# TC37X register map
File version: 1.0.0
CPU: CM4 r0p1, little endian, MPU, FPU, VTOR, 3 interrupt priority bits
Registers are 16-bit, read-write, reset 0x0 unless marked. A register's access mark holds for its fields unless they carry their own. Offsets are from the block's base; [hi:lo] are bit positions; {n}, {i} and the like mark numbered series; 'fields as' and 'values as' point back to an identical list.

## SCU — ystem Control Unit
Base 0xF0036000
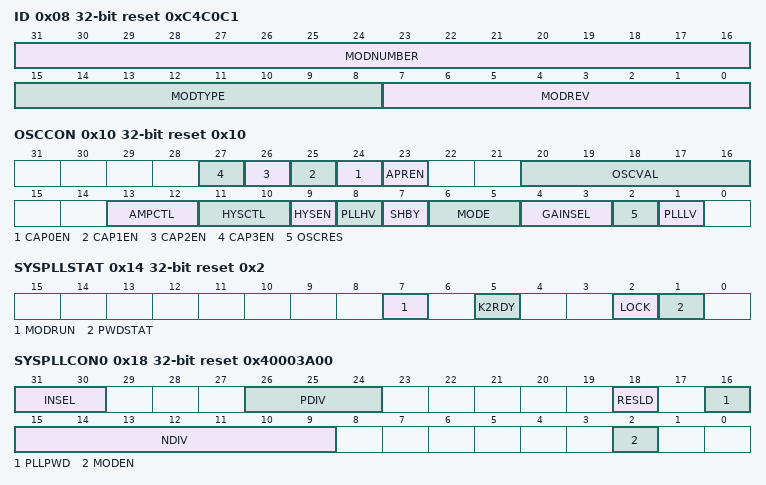
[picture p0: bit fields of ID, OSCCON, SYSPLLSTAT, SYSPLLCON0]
0x08 ID 32-bit ro reset 0xC4C0C1 — Identification Register
  [31:16] MODNUMBER — Module Number - MODNUMBER
  [15:8] MODTYPE — Module Type - MODTYPE
  [7:0] MODREV — Module Revision Number - MODREV
0x10 OSCCON 32-bit reset 0x10 (reset mask 0xFFFFF0F0) — OSC Control Register
  [n+24] CAP{n}EN (n=0..3) — Capacitance {n} Enable - CAP{n}EN
  [23] APREN — Amplitude Regulation Enable - APREN
  [20:16] OSCVAL — OSC Frequency Value - OSCVAL
  [13:12] AMPCTL — Amplitude Control
  [11:10] HYSCTL — Hysteresis Control
  [9] HYSEN — Hysteresis Enable
  [8] PLLHV ro — Oscillator for PLL Valid High Status Bit - PLLHV
  [7] SHBY — Shaper Bypass - SHBY
  [6:5] MODE — Oscillator Mode - MODE
  [4:3] GAINSEL — Oscillator Gain Selection - GAINSEL
  [2] OSCRES wo — Oscillator Watchdog Reset - OSCRES
  [1] PLLLV ro — Oscillator for PLL Valid Low Status Bit - PLLLV
0x14 SYSPLLSTAT 32-bit ro reset 0x2 — System PLL Status Register
  [7] MODRUN — Modulation Run - MODRUN
  [5] K2RDY — K2 Divider Ready Status - K2RDY
  [2] LOCK — System PLL Lock Status - LOCK
  [1] PWDSTAT — System PLL Power-saving Mode Status - PWDSTAT
0x18 SYSPLLCON0 32-bit reset 0x40003A00 — System PLL Configuration 0 Register
  [31:30] INSEL — Input Selection - INSEL
  [26:24] PDIV — P-Divider Value - PDIV
  [18] RESLD wo — Restart DCO Lock Detection - RESLD
  [16] PLLPWD — System PLL Power Saving Mode - PLLPWD
  [15:9] NDIV — N-Divider Value - NDIV
  [2] MODEN — Modulation Enable - MODEN
0x1C SYSPLLCON1 32-bit reset 0x5 — System PLL Configuration 1 Register
  [2:0] K2DIV — K2-Divider Value - K2DIV
0x20 SYSPLLCON2 32-bit reset 0x6000 — System PLL Configuration 2 Register
  [15:0] MODCFG — Modulation Configuration - MODCFG
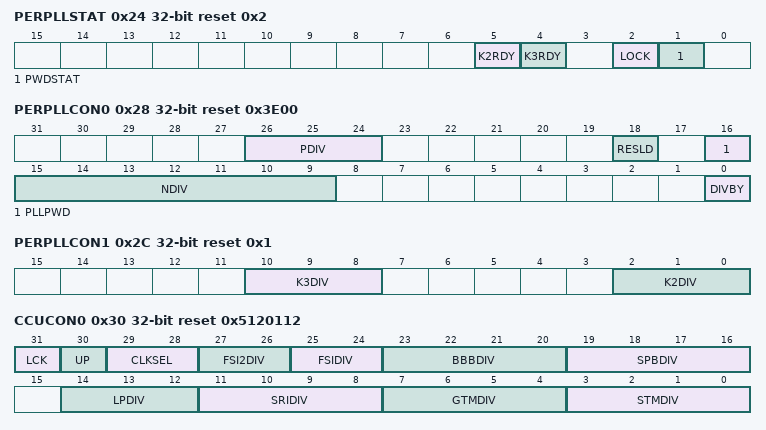
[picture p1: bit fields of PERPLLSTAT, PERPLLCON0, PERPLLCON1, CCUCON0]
0x24 PERPLLSTAT 32-bit ro reset 0x2 — Peripheral PLL Status Register
  [5] K2RDY — K2 Divider Ready Status - K2RDY
  [4] K3RDY — K3 Divider Ready Status - K3RDY
  [2] LOCK — Peripheral PLL Lock Status - LOCK
  [1] PWDSTAT — Peripheral PLL Power-saving Mode Status - PWDSTAT
0x28 PERPLLCON0 32-bit reset 0x3E00 — Peripheral PLL Configuration 0 Register
  [26:24] PDIV — P-Divider Value - PDIV
  [18] RESLD wo — Restart DCO Lock Detection - RESLD
  [16] PLLPWD — Peripheral PLL Power Saving Mode - PLLPWD
  [15:9] NDIV — N-Divider Value - NDIV
  [0] DIVBY — Divider Bypass - DIVBY
0x2C PERPLLCON1 32-bit reset 0x1 — Peripheral PLL Configuration 1 Register
  [10:8] K3DIV — K3-Divider Value - K3DIV
  [2:0] K2DIV — K2-Divider Value - K2DIV
0x30 CCUCON0 32-bit reset 0x5120112 — CCU Clock Control Register 0
  [31] LCK ro — Lock Status - LCK
  [30] UP wo — Update Request - UP
  [29:28] CLKSEL — Clock Selection for Source - CLKSEL
  [27:26] FSI2DIV — FSI2 Divider Reload Value - FSI2DIV
  [25:24] FSIDIV — FSI Divider Reload Value - FSIDIV
  [23:20] BBBDIV — BBB Divider Reload Value - BBBDIV
  [19:16] SPBDIV — SPB Divider Reload Value - SPBDIV
  [14:12] LPDIV — Low Power Divider Reload Value - LPDIV
  [11:8] SRIDIV — SRI Divider Reload Value - SRIDIV
  [7:4] GTMDIV — GTM Divider Reload Value - GTMDIV
  [3:0] STMDIV — STM Divider Reload Value - STMDIV
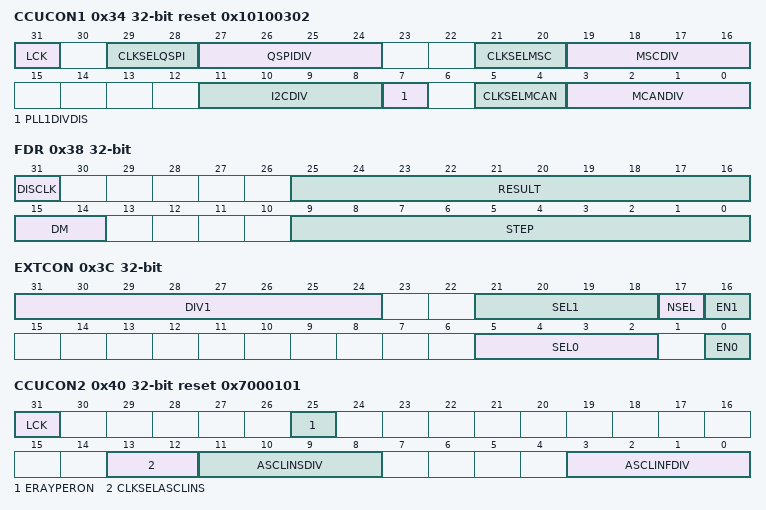
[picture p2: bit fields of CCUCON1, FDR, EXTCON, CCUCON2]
0x34 CCUCON1 32-bit reset 0x10100302 — CCU Clock Control Register 1
  [31] LCK ro — Lock Status - LCK
  [29:28] CLKSELQSPI — Clock Selection for QSPI - CLKSELQSPI
  [27:24] QSPIDIV — QSPI Divider Reload Value - QSPIDIV
  [21:20] CLKSELMSC — Clock Selection for MSC - CLKSELMSC
  [19:16] MSCDIV — MSC Divider Reload Value - MSCDIV
  [11:8] I2CDIV — I2C Divider Reload Value - I2CDIV
  [7] PLL1DIVDIS — Divider Disable for fPLL1 - PLL1DIVDIS
  [5:4] CLKSELMCAN — Clock Selection for MCAN - CLKSELMCAN
  [3:0] MCANDIV — MCAN Divider Reload Value - MCANDIV
0x38 FDR 32-bit — Fractional Divider Register
  [31] DISCLK — Disable Clock - DISCLK
  [25:16] RESULT ro — Result Value - RESULT
  [15:14] DM — Divider Mode - DM
  [9:0] STEP — Step Value - STEP
0x3C EXTCON 32-bit — External Clock Control Register
  [31:24] DIV1 — External Clock Divider for EXTCLK1 - DIV1
  [21:18] SEL1 — External Clock Select for EXTCLK1 - SEL1
  [17] NSEL — Negation Selection - NSEL
  [16] EN1 — External Clock Enable for EXTCLK1 - EN1
  [5:2] SEL0 — External Clock Select for EXTCLK0 - SEL0
  [0] EN0 — External Clock Enable for EXTCLK0 - EN0
0x40 CCUCON2 32-bit reset 0x7000101 — CCU Clock Control Register 2
  [31] LCK ro — Lock Status - LCK
  [25] ERAYPERON — Power Safe SwitchOff for ERAY Clock - ERAYPERON
  [13:12] CLKSELASCLINS — Clock Selection for ASCLINS - CLKSELASCLINS
  [11:8] ASCLINSDIV — ASCLIN Slow Divider Reload Value - ASCLINSDIV
  [3:0] ASCLINFDIV — ASCLIN Fast Divider Reload Value - ASCLINFDIV
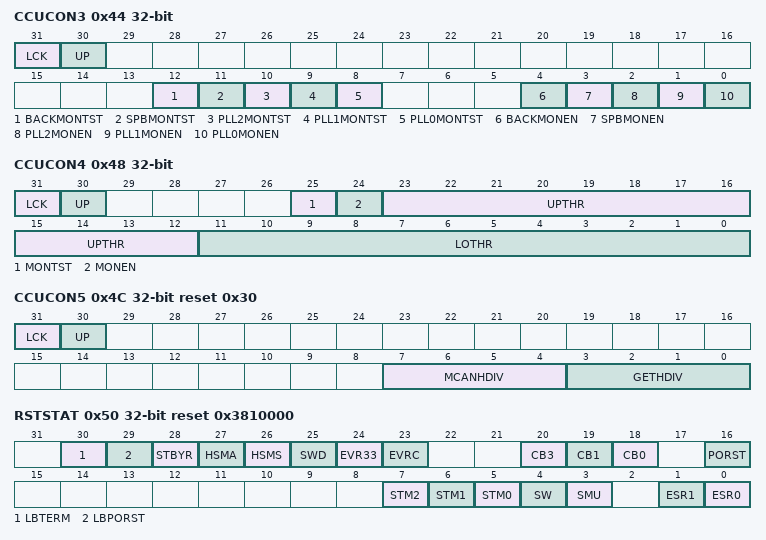
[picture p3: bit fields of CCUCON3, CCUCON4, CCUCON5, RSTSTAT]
0x44 CCUCON3 32-bit — CCU Clock Control Register 3
  [31] LCK ro — Lock Status - LCK
  [30] UP wo — Update Request - UP
  [12] BACKMONTST — Backup Clock Monitor Test - BACKMONTST
  [11] SPBMONTST — SPB Clock Monitor Test - SPBMONTST
  [10] PLL2MONTST — PLL2 Clock Monitor Test - PLL2MONTST
  [9] PLL1MONTST — PLL1 Clock Monitor Test - PLL1MONTST
  [8] PLL0MONTST — PLL0 Clock Monitor Test - PLL0MONTST
  [4] BACKMONEN — Backup Clock Monitor Enable - BACKMONEN
  [3] SPBMONEN — SPB Clock Monitor Enable - SPBMONEN
  [2] PLL2MONEN — PLL2 Clock Monitor Enable - PLL2MONEN
  [1] PLL1MONEN — PLL1 Clock Monitor Enable - PLL1MONEN
  [0] PLL0MONEN — PLL0 Clock Monitor Enable - PLL0MONEN
0x48 CCUCON4 32-bit — CCU Clock Control Register 4
  [31] LCK ro — Lock Status - LCK
  [30] UP wo — Update Request - UP
  [25] MONTST — Backup Clock Monitor Test - MONTST
  [24] MONEN — Backup Clock Monitor Enable - MONEN
  [23:12] UPTHR — Backup Clock Monitor Upper Threshold - UPTHR
  [11:0] LOTHR — Backup Clock Monitor Lower Threshold - LOTHR
0x4C CCUCON5 32-bit reset 0x30 — CCU Clock Control Register 5
  [31] LCK ro — Lock Status - LCK
  [30] UP wo — Update Request - UP
  [7:4] MCANHDIV — MCANH Divider Reload Value - MCANHDIV
  [3:0] GETHDIV — GETH Divider Reload Value - GETHDIV
0x50 RSTSTAT 32-bit ro reset 0x3810000 (reset mask 0xF00FFFFF)
  [30] LBTERM — LBIST was properly terminated
  [29] LBPORST — LBIST termination due to PORST
  [28] STBYR — Reset Request Trigger Reset Status for Standby Regulator Watchdog (STBYR) - STBYR
  [27] HSMA — Reset Request Trigger Reset Status for HSM Application Reset (HSM A) - HSMA
  [26] HSMS — Reset Request Trigger Reset Status for HSM System Reset (HSM S) - HSMS
  [25] SWD — Reset Request Trigger Reset Status for Supply Watchdog (SWD) - SWD
  [24] EVR33 — Reset Request Trigger Reset Status for EVR33 - EVR33
  [23] EVRC — Reset Request Trigger Reset Status for EVRC - EVRC
  [20] CB3 — Reset Request Trigger Reset Status for Cerberus Application Reset - CB3
  [19] CB1 — Reset Request Trigger Reset Status for Cerberus Debug Reset - CB1
  [18] CB0 — Reset Request Trigger Reset Status for Cerberus System Reset - CB0
  [16] PORST — Reset Request Trigger Reset Status for PORST - PORST
  [7] STM2 — Reset Request Trigger Reset Status for STM2 Compare Match (If Product has STM2) - STM2
  [6] STM1 — Reset Request Trigger Reset Status for STM1 Compare Match (If Product has STM1) - STM1
  [5] STM0 — Reset Request Trigger Reset Status for STM0 Compare Match - STM0
  [4] SW — Reset Request Trigger Reset Status for SW - SW
  [3] SMU — Reset Request Trigger Reset Status for SMU - SMU
  [1] ESR1 — Reset Request Trigger Reset Status for ESR1 - ESR1
  [0] ESR0 — Reset Request Trigger Reset Status for ESR0 - ESR0
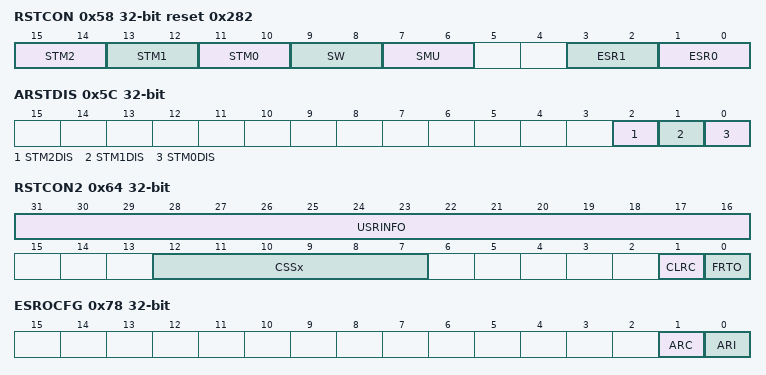
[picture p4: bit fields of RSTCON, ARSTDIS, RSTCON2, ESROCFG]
0x58 RSTCON 32-bit reset 0x282
  [15:14] STM2 — STM2 Reset Request Trigger Reset Configuration (If Product has STM2) - STM2
  [13:12] STM1 — STM1 Reset Request Trigger Reset Configuration (If Product has STM1) - STM1
  [11:10] STM0 — STM0 Reset Request Trigger Reset Configuration - STM0
  [9:8] SW — SW Reset Request Trigger Reset Configuration - SW
  [7:6] SMU — SMU Reset Request Trigger Reset Configuration - SMU
  [3:2] ESR1 — ESR1 Reset Request Trigger Reset Configuration - ESR1
  [1:0] ESR0 — ESR0 Reset Request Trigger Reset Configuration - ESR0
0x5C ARSTDIS 32-bit
  [2] STM2DIS — STM2 Disable Reset - STM2DIS
  [1] STM1DIS — STM1 Disable Reset - STM1DIS
  [0] STM0DIS — STM0 Disable Reset - STM0DIS
0x60 SWRSTCON 32-bit
  [1] SWRSTREQ wo — Software Reset Request - SWRSTREQ
0x64 RSTCON2 32-bit
  [31:16] USRINFO — User Information - USRINFO
  [12:7] CSSx ro — CPU x Shutdown State Reached - CSSx
  [1] CLRC wo — Clear Cold Reset Status - CLRC
  [0] FRTO — Force Reset Timeout - FRTO
0x68 RSTCON3 32-bit
0x70 ESRCFG0 32-bit reset 0x100 — ESR0 Input Configuration Register
  [8:7] EDCON — Edge Detection Control - EDCON
0x74 ESRCFG1 32-bit reset 0x100 — ESR1 Input Configuration Register
  [8:7] EDCON — Edge Detection Control - EDCON
0x78 ESROCFG 32-bit (reset mask 0xFFFFFFF0) — ESR Output Configuration Register
  [1] ARC wo — Application Reset Indicator Clear - ARC
  [0] ARI ro — Application Reset Indicator - ARI
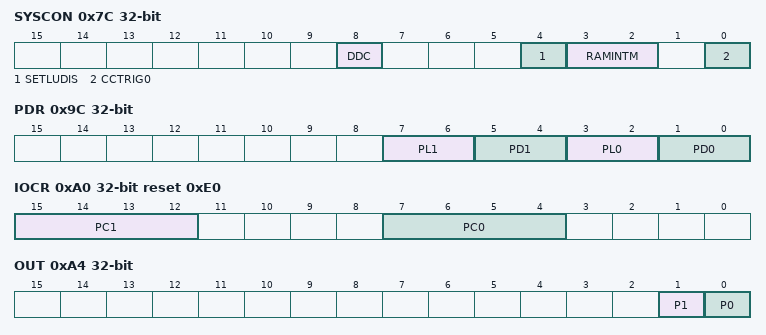
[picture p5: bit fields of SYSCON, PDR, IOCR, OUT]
0x7C SYSCON 32-bit — System Control Register
  [8] DDC — Disable DXCPL - DDC
  [4] SETLUDIS wo — Set Latch Update Disable - SETLUDIS
  [3:2] RAMINTM wo — RAM Integrity Modify - RAMINTM
  [0] CCTRIG0 — Capture Compare Trigger 0 - CCTRIG0
{0x68+4i} CCUCON{i} 32-bit (i=6..8) — CCU Clock Control Register {i}
  [5:0] CPU{i-6}DIV — CPU{i-6} Divider Reload Value - CPU{i-6}DIV
0x9C PDR 32-bit — ESR Pad Driver Mode Register
  [7:6] PL1 — Pad Level Selection for ESR Pins 1 - PL1
  [5:4] PD1 — Pad Driver Mode for ESR Pins 1 - PD1
  [3:2] PL0 — Pad Level Selection for ESR Pins 0 - PL0
  [1:0] PD0 — Pad Driver Mode for ESR Pins 0 - PD0
0xA0 IOCR 32-bit reset 0xE0 (reset mask 0xFFFF0FFF) — Input/Output Control Register
  [15:12] PC1 — Control for ESR1 Pin - PC1
  [7:4] PC0 — Control for ESR0 Pin - PC0
0xA4 OUT 32-bit — ESR Output Register
  [1] P1 — Output Bit 1 - P1
  [0] P0 — Output Bit 0 - P0
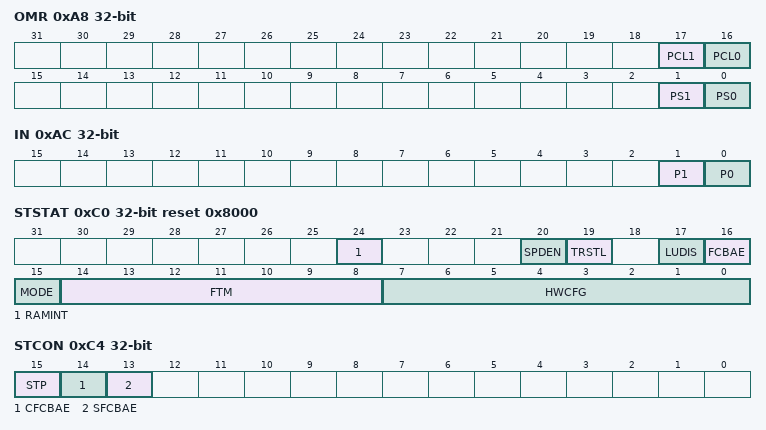
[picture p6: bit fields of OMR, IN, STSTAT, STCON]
0xA8 OMR 32-bit wo — ESR Output Modification Register
  [17] PCL1 — ESRx Pin Clear Bit 1 - PCL1
  [16] PCL0 — ESRx Pin Clear Bit 0 - PCL0
  [1] PS1 — ESRx Pin Set Bit 1 - PS1
  [0] PS0 — ESRx Pin Set Bit 0 - PS0
0xAC IN 32-bit ro (reset mask 0xFFFFFFF0) — ESR Input Register
  [1] P1 — Input Bit 1 - P1
  [0] P0 — Input Bit 0 - P0
0xC0 STSTAT 32-bit ro reset 0x8000 (reset mask 0xFFF0FF00)
  [24] RAMINT — RAM Content Security Integrity - RAMINT
  [20] SPDEN — Single Pin DAP Mode Enable - SPDEN
  [19] TRSTL — TRSTL Status - TRSTL
  [17] LUDIS — Latch Update Disable - LUDIS
  [16] FCBAE — Flash Config. Sector Access Enable - FCBAE
  [15] MODE — MODE - MODE
  [14:8] FTM — Firmware Test Setting - FTM
  [7:0] HWCFG — Hardware Configuration Setting - HWCFG
0xC4 STCON 32-bit — Start-up Configuration Register
  [15] STP — Start-up Protection Setting - STP
  [14] CFCBAE wo — Clear Flash Config. Sector Access Enable - CFCBAE
  [13] SFCBAE wo — Set Flash Config. Sector Access Enable - SFCBAE
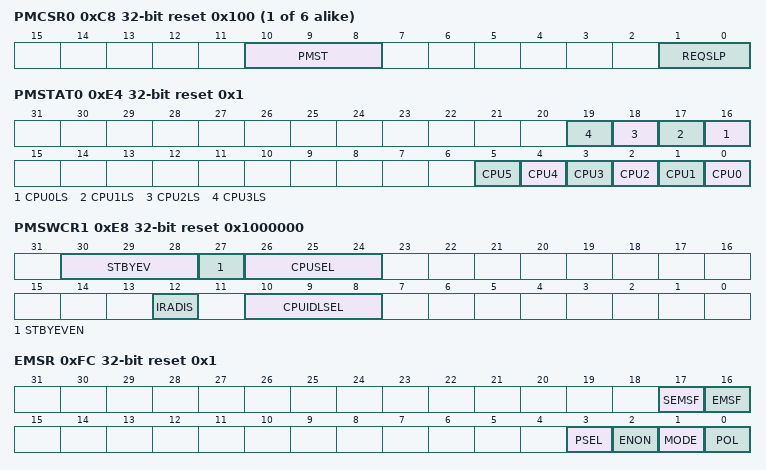
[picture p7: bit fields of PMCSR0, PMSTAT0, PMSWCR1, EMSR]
{0xC8+4i} PMCSR{i} 32-bit reset 0x100 (i=0..5) — Power Management Control and Status Register
  [10:8] PMST ro — Power management Status - PMST
  [1:0] REQSLP — Idle Mode and Sleep Mode Request - REQSLP
0xE4 PMSTAT0 32-bit ro reset 0x1 — Power Management Status Register 0
  [n+16] CPU{n}LS (n=0..3) — CPU{n}LS Status - CPU{n}LS
  [n] CPU{n} (n=0..5) — CPU{n} Status - CPU{n}
0xE8 PMSWCR1 32-bit reset 0x1000000 — Standby and Wake-up Control Register 1
  [30:28] STBYEV — Standby Entry Event Configuration - STBYEV
  [27] STBYEVEN wo — Standby Entry Event configuration enable - STBYEVEN
  [26:24] CPUSEL — CPU selection for Sleep and Standby mode - CPUSEL
  [12] IRADIS — Idle-Request-Acknowledge Sequence Disable - IRADIS
  [10:8] CPUIDLSEL — CPU selection for Idle mode - CPUIDLSEL
0xFC EMSR 32-bit reset 0x1 — Emergency Stop Register
  [17] SEMSF ro — SMU Emergency Stop Flag - SEMSF
  [16] EMSF ro — Emergency Stop Flag - EMSF
  [3] PSEL — PORT Select - PSEL
  [2] ENON — Enable ON - ENON
  [1] MODE — Mode Selection - MODE
  [0] POL — Input Polarity - POL
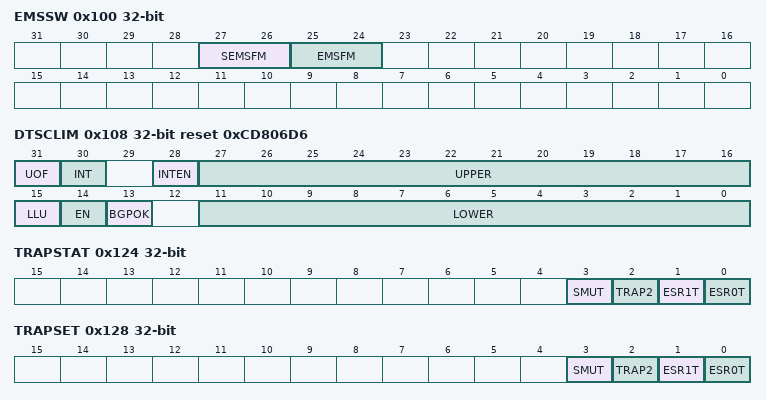
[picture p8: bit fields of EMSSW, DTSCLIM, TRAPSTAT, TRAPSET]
0x100 EMSSW 32-bit — Emergency Stop Software set and clear register
  [27:26] SEMSFM wo — SMU Emergency Stop Flag Modification - SEMSFM
  [25:24] EMSFM wo — Emergency Stop Flag Modification - EMSFM
0x104 DTSCSTAT 32-bit ro — Core Die Temperature Sensor Status Register
  [11:0] RESULT — Result of the DTSC Measurement - RESULT
0x108 DTSCLIM 32-bit reset 0xCD806D6 — Core Die Temperature Sensor Limit Register
  [31] UOF — DTSC Upper Limit Overflow - UOF
  [30] INT — DTSC Interrupt status flag
  [28] INTEN — DTSC Interrupt Enable
  [27:16] UPPER — DTSC Upper Limit - UPPER
  [15] LLU — DTSC Lower Limit Underflow - LLU
  [14] EN — DTSC Enable
  [13] BGPOK ro — DTSC Bandgap OK
  [11:0] LOWER — DTSC Lower Limit - LOWER
0x120 TRAPDIS1 32-bit reset 0xFFFF — Trap Disable Register 1
0x124 TRAPSTAT 32-bit ro (reset mask 0xFFFFFFF0) — Trap Status Register
  [3] SMUT — SMU Alarm Trap Request Flag - SMUT
  [2] TRAP2 — Trap Bit 2 Request Flag - TRAP2
  [1] ESR1T — ESR1 Trap Request Flag - ESR1T
  [0] ESR0T — ESR0 Trap Request Flag - ESR0T
0x128 TRAPSET 32-bit wo
  [3] SMUT — Set Trap Request Flag SMUT - SMUT
  [2] TRAP2 — Set Trap Request Flag TRAP2 - TRAP2
  [1] ESR1T — Set Trap Request Flag ESR1T - ESR1T
  [0] ESR0T — Set Trap Request Flag ESR0T - ESR0T
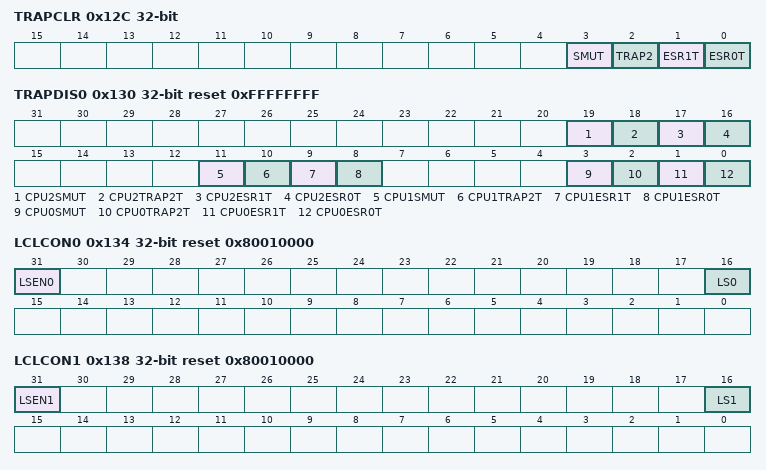
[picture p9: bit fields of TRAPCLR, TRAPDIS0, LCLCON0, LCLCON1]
0x12C TRAPCLR 32-bit wo — Trap Clear Register
  [3] SMUT — Clear Trap Request Flag SMUT - SMUT
  [2] TRAP2 — Clear Trap Request Flag TRAP2 - TRAP2
  [1] ESR1T — Clear Trap Request Flag ESR1T - ESR1T
  [0] ESR0T — Clear Trap Request Flag ESR0T - ESR0T
0x130 TRAPDIS0 32-bit reset 0xFFFFFFFF — Trap Disable Register 0
  [19] CPU2SMUT — Disable Trap Request SMUT on CPU2 (If product has CPU2) - CPU2SMUT
  [18] CPU2TRAP2T — Disable Trap Request TRAP2T on CPU2 (If product has CPU2) - CPU2TRAP2T
  [17] CPU2ESR1T — Disable Trap Request ESR1T on CPU2 (If product has CPU2) - CPU2ESR1T
  [16] CPU2ESR0T — Disable Trap Request ESR0T on CPU2 (If product has CPU2) - CPU2ESR0T
  [11] CPU1SMUT — Disable Trap Request SMUT on CPU1 (If product has CPU1) - CPU1SMUT
  [10] CPU1TRAP2T — Disable Trap Request TRAP2T on CPU1 (If product has CPU1) - CPU1TRAP2T
  [9] CPU1ESR1T — Disable Trap Request ESR1T on CPU1 (If product has CPU1) - CPU1ESR1T
  [8] CPU1ESR0T — Disable Trap Request ESR0T on CPU1 (If product has CPU1) - CPU1ESR0T
  [3] CPU0SMUT — Disable Trap Request SMUT on CPU0 - CPU0SMUT
  [2] CPU0TRAP2T — Disable Trap Request TRAP2T on CPU0 - CPU0TRAP2T
  [1] CPU0ESR1T — Disable Trap Request ESR1T on CPU0 - CPU0ESR1T
  [0] CPU0ESR0T — Disable Trap Request ESR0T on CPU0 - CPU0ESR0T
0x134 LCLCON0 32-bit reset 0x80010000 — LCL CPU0 and CPU2 Control Register
  [31] LSEN0 — Lockstep Enable - LSEN0
  [16] LS0 ro — Lockstep Mode Status - LS0
0x138 LCLCON1 32-bit reset 0x80010000 — LCL CPU1 and CPU3 Control Register
  [31] LSEN1 — Lockstep Enable - LSEN1
  [16] LS1 ro — Lockstep Mode Status - LS1
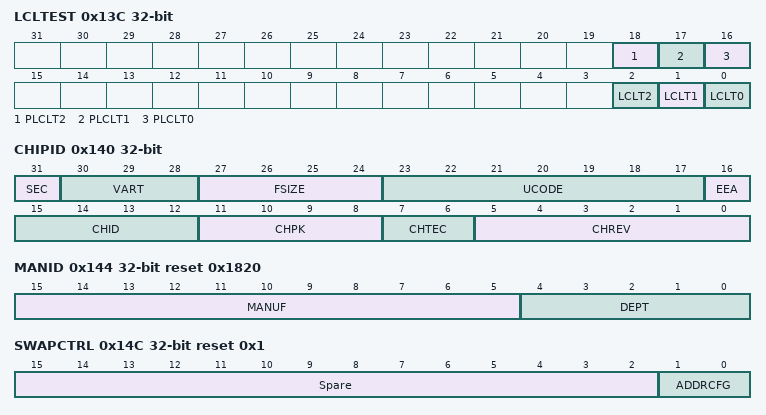
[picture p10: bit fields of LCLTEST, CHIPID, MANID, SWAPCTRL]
0x13C LCLTEST 32-bit
  [18] PLCLT2 wo — PFI2 Lockstep Test
  [17] PLCLT1 wo — PFI1 Lockstep Test
  [16] PLCLT0 wo — PFI0 Lockstep Test
  [2] LCLT2 wo — LCL2 Lockstep Test - LCLT2
  [1] LCLT1 wo — LCL1 Lockstep Test - LCLT1
  [0] LCLT0 wo — LCL0 Lockstep Test - LCLT0
0x140 CHIPID 32-bit reset not defined — Chip Identification Register
  [31] SEC — Security Device Available - SEC
  [30:28] VART — Variant - VART
  [27:24] FSIZE — Program Flash Size - FSIZE
  [23:17] UCODE — uCode Version - UCODE
  [16] EEA ro — Emulation or ADAS Extension Available - EEA
  [15:12] CHID — Chip Product - CHID
  [11:8] CHPK — Chip Package - CHPK
  [7:6] CHTEC ro — Chip Family - CHTEC
  [5:0] CHREV ro — Chip Revision Number - CHREV
0x144 MANID 32-bit ro reset 0x1820 — Manufacturer Identification Register
  [15:5] MANUF — Manufacturer Identification Number - MANUF
  [4:0] DEPT — Department Identification Number - DEPT
0x14C SWAPCTRL 32-bit reset 0x1 — Address Map Control Register
  [15:2] Spare — Spare address configuration registers
  [1:0] ADDRCFG — Address Configuration
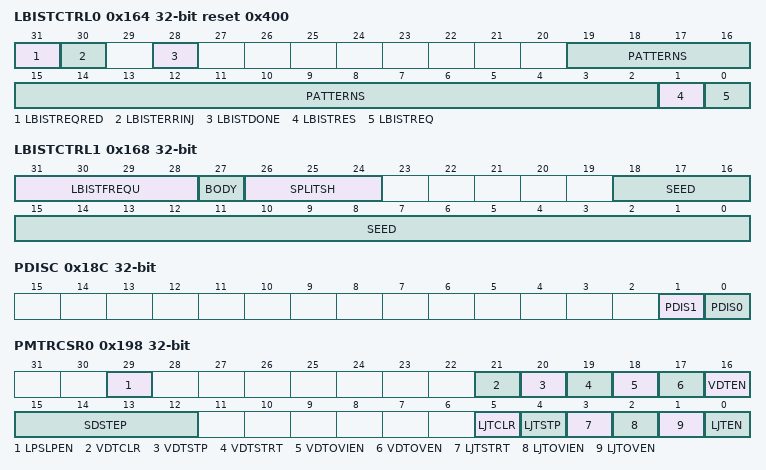
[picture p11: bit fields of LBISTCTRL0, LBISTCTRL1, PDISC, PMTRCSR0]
0x164 LBISTCTRL0 32-bit reset 0x400 (reset mask 0xEFF00003) — Logic BIST Control 0 Register
  [31] LBISTREQRED — LBIST Request Redundancy
  [30] LBISTERRINJ — LBIST / Test-Mode Alarm Error Injection
  [28] LBISTDONE ro — LBIST Execution Indicator - LBISTDONE
  [19:2] PATTERNS — LBIST Pattern Number - PATTERNS
  [1] LBISTRES wo — LBIST-Reset- LBISTRES
  [0] LBISTREQ wo — LBIST Request - LBISTREQ
0x168 LBISTCTRL1 32-bit — Logic BIST Control 1 Register
  [31:28] LBISTFREQU — LBIST Frequency Selection - LBISTFREQU
  [27] BODY — Body Application Indicator - BODY
  [26:24] SPLITSH — LBIST Split-Shift Selection - SPLITSH
  [18:0] SEED — LBIST Seed - SEED
0x16C LBISTCTRL2 32-bit — Logic BIST Control 2 Register
  [11:0] LENGTH — LBIST Maximum Scan-Chain Length - LENGTH
0x170 LBISTCTRL3 32-bit ro — Logic BIST Control 3 Register
  [31:0] SIGNATURE — LBIST Signature - SIGNATURE
0x184 STMEM1 32-bit — Start-up Memory Register 1
  [31:0] MEM — Memory - MEM
0x188 STMEM2 32-bit — Start-up Memory Register 2
  [31:0] MEM — Memory - MEM
0x18C PDISC 32-bit — Pad Disable Control Register
  [1] PDIS1 — Pad Disable for ESR Pin 1 - PDIS1
  [0] PDIS0 — Pad Disable for ESR Pin 0 - PDIS0
0x198 PMTRCSR0 32-bit — Power Management Transition Control and Status Register 0
  [29] LPSLPEN — EVRC Low Power Mode activation on a Sleep Request - LPSLPEN
  [21] VDTCLR wo — Voltage Droop Timer Clear - VDTCLR
  [20] VDTSTP — Voltage Droop Timer Stop - VDTSTP
  [19] VDTSTRT — Voltage Droop Timer Start - VDTSTRT
  [18] VDTOVIEN — Voltage Droop Timer Overflow Interrupt Enable - VDTOVIEN
  [17] VDTOVEN — Voltage Droop Timer Overflow Enable - VDTOVEN
  [16] VDTEN — Voltage Droop Timer Enable - VDTEN
  [15:12] SDSTEP — Droop Voltage Step(vdroop_step_i) - SDSTEP
  [5] LJTCLR wo — Load Jump Timer Clear - LJTCLR
  [4] LJTSTP — Load Jump Timer Stop - LJTSTP
  [3] LJTSTRT — Load Jump Timer Start - LJTSTRT
  [2] LJTOVIEN — Load Jump Timer Overflow Interrupt Enable - LJTOVIEN
  [1] LJTOVEN — Load Jump Timer Overflow Enable - LJTOVEN
  [0] LJTEN — Load Jump Timer Enable - LJTEN
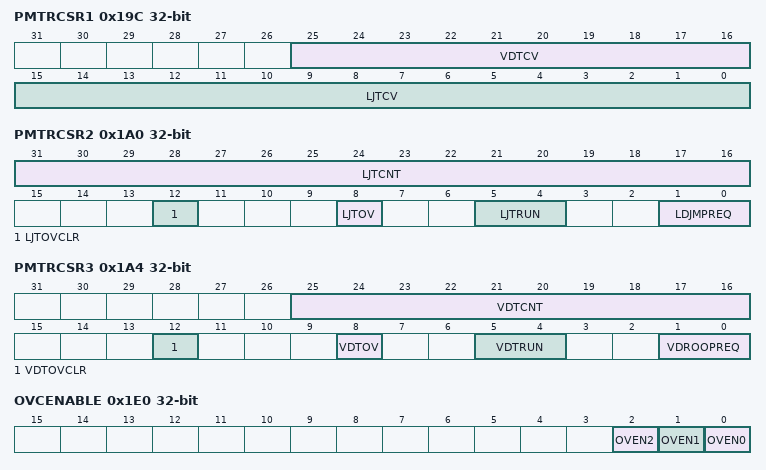
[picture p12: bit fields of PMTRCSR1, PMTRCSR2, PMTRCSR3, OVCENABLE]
0x19C PMTRCSR1 32-bit — Power Management Transition Control and Status Register 1
  [25:16] VDTCV — Voltage Droop Timer Compare Setpoint Value - VDTCV
  [15:0] LJTCV — Load Jump Timer Compare Setpoint Value - LJTCV
0x1A0 PMTRCSR2 32-bit — Power Management Transition Control and Status Register 2
  [31:16] LJTCNT ro — Load Jump Timer Value - LJTCNT
  [12] LJTOVCLR wo — Load Jump Timer Overflow Status Clear - LJTOVCLR
  [8] LJTOV ro — Load Jump Timer Overflow Status - LJTOV
  [5:4] LJTRUN ro — Load Jump Timer Run Status - LJTRUN
  [1:0] LDJMPREQ — Load Jump Request - LDJMPREQ
0x1A4 PMTRCSR3 32-bit — Power Management Transition Control and Status Register 3
  [25:16] VDTCNT ro — Voltage Droop Timer Value - VDTCNT
  [12] VDTOVCLR wo — Voltage Droop Timer Overflow Status Clear - VDTOVCLR
  [8] VDTOV ro — Voltage Droop Timer Overflow Status - VDTOV
  [5:4] VDTRUN ro — Voltage Droop Timer Run Status - VDTRUN
  [1:0] VDROOPREQ — Voltage Droop Request - VDROOPREQ
{0x1B4+4i} STMEM{i} 32-bit (i=3..6) — Start-up Memory Register {i}
  [31:0] MEM — Memory - MEM
0x1E0 OVCENABLE 32-bit — Overlay Enable Register
  [2] OVEN2 — Overlay Enable 2 (If product has CPU2) - OVEN2
  [1] OVEN1 — Overlay Enable 1 (If product has CPU1) - OVEN1
  [0] OVEN0 — Overlay Enable 0 - OVEN0
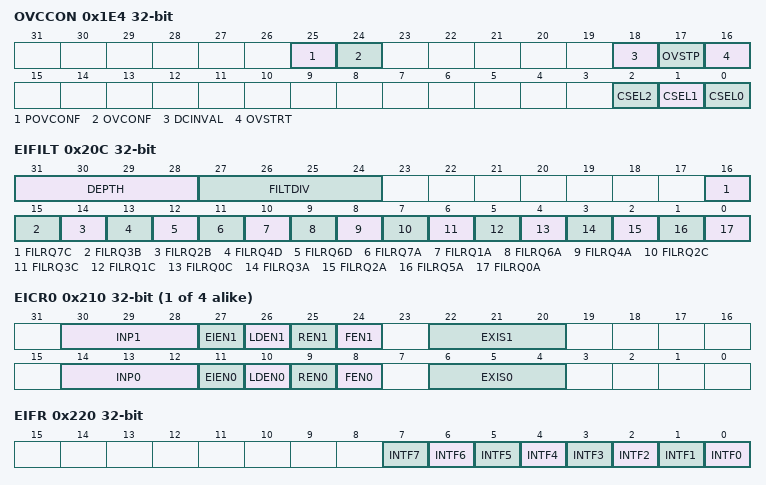
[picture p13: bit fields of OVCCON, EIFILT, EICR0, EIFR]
0x1E4 OVCCON 32-bit — Overlay Control Register
  [25] POVCONF wo — Write Protection for OVCONF - POVCONF
  [24] OVCONF — Overlay Configured - OVCONF
  [18] DCINVAL wo — Data Cache Invalidate - DCINVAL
  [17] OVSTP wo — Overlay Stop - OVSTP
  [16] OVSTRT wo — Overlay Start - OVSTRT
  [2] CSEL2 wo — CPU Select 2 (If product has CPU2) - CSEL2
  [1] CSEL1 wo — CPU Select 1 (If product has CPU1) - CSEL1
  [0] CSEL0 wo — CPU Select 0 - CSEL0
0x20C EIFILT 32-bit — External Input Filter Register
  [31:28] DEPTH — Digital Glitch Filter Depth - DEPTH
  [27:24] FILTDIV — Digital Glitch Filter Clock Predivider - FILTDIV
  [16] FILRQ7C — Filter Enable for REQ7C - FILRQ7C
  [15] FILRQ3B — Filter Enable for REQ3B - FILRQ3B
  [14] FILRQ2B — Filter Enable for REQ2B - FILRQ2B
  [13] FILRQ4D — Filter Enable for REQ4D - FILRQ4D
  [12] FILRQ6D — Filter Enable for REQ6D - FILRQ6D
  [11] FILRQ7A — Filter Enable for REQ7A - FILRQ7A
  [10] FILRQ1A — Filter Enable for REQ1A - FILRQ1A
  [9] FILRQ6A — Filter Enable for REQ6A - FILRQ6A
  [8] FILRQ4A — Filter Enable for REQ4A - FILRQ4A
  [7] FILRQ2C — Filter Enable for REQ2C - FILRQ2C
  [6] FILRQ3C — Filter Enable for REQ3C - FILRQ3C
  [5] FILRQ1C — Filter Enable for REQ1C - FILRQ1C
  [4] FILRQ0C — Filter Enable for REQ0C - FILRQ0C
  [3] FILRQ3A — Filter Enable for REQ3A - FILRQ3A
  [2] FILRQ2A — Filter Enable for REQ2A - FILRQ2A
  [1] FILRQ5A — Filter Enable for REQ5A - FILRQ5A
  [0] FILRQ0A — Filter Enable for REQ0A - FILRQ0A
{0x210+4i} EICR{i} 32-bit (i=0..3) — External Input Channel Register {i}
  [30:28] INP1 — Input Node Pointer - INP1
  [27] EIEN1 — External Input Enable 1 - EIEN1
  [26] LDEN1 — Level Detection Enable 1 - LDEN1
  [25] REN1 — Rising Edge Enable 1 - REN1
  [24] FEN1 — Falling Edge Enable 1 - FEN1
  [22:20] EXIS1 — External Input Selection 1 - EXIS1
  [14:12] INP0 — Input Node Pointer - INP0
  [11] EIEN0 — External Input Enable 0 - EIEN0
  [10] LDEN0 — Level Detection Enable 0 - LDEN0
  [9] REN0 — Rising Edge Enable 0 - REN0
  [8] FEN0 — Falling Edge Enable 0 - FEN0
  [6:4] EXIS0 — External Input Selection 0 - EXIS0
0x220 EIFR 32-bit ro — External Input Flag Register
  [n] INTF{n} (n=0..7) — External Event Flag of Channel {n} - INTF{n}
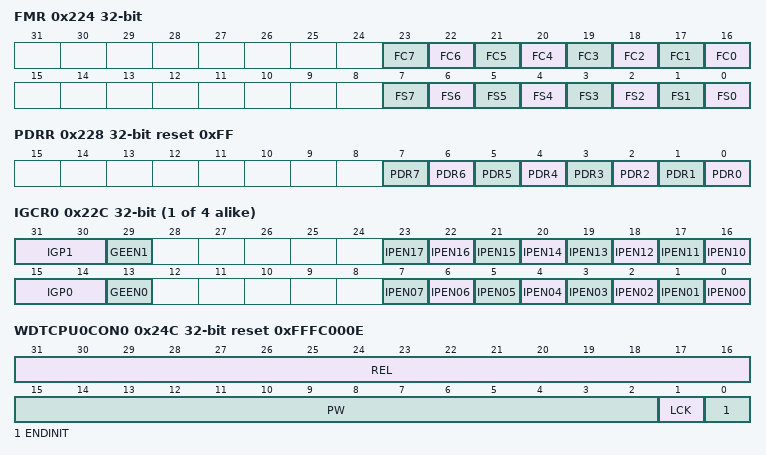
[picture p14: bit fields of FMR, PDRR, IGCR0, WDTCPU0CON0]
0x224 FMR 32-bit wo — Flag Modification Register
  [n+16] FC{n} (n=0..7) — Clear Flag INTFx for Channel {n} - FC{n}
  [n] FS{n} (n=0..7) — Set Flag INTFx for Channel {n} - FS{n}
0x228 PDRR 32-bit ro reset 0xFF — Pattern Detection Result Register
  [n] PDR{n} (n=0..7) — Pattern Detection Result of Channel {n} - PDR{n}
{0x22C+4i} IGCR{i} 32-bit (i=0..3) — Flag Gating Register {i}
  [31:30] IGP1 — Interrupt Gating Pattern 1 - IGP1
  [29] GEEN1 — Generate Event Enable 1 - GEEN1
  [n+6] IPEN{n} (n=10..17) — Interrupt Pattern Enable for Channel 1 - IPEN{n}
  [15:14] IGP0 — Interrupt Gating Pattern 0 - IGP0
  [13] GEEN0 — Generate Event Enable 0 - GEEN0
  [n] IPEN{n:02} (n=0..7) — Flag Pattern Enable for Channel 0 - IPEN{n:02}
0x24C WDTCPU0CON0 32-bit reset 0xFFFC000E
  [31:16] REL — Reload Value for the WDT (also Time Check Value) - REL
  [15:2] PW — User-Definable Password Field for Access to WDTxCON0 - PW
  [1] LCK — Lock Bit to Control Access to WDTxCON0 - LCK
  [0] ENDINIT — End-of-Initialization Control Bit - ENDINIT
0x250 WDTCPU0CON1 32-bit
  [15:9] TCTR — Timer Check Tolerance Request - TCTR
  [8] TCR — Counter Check Request Bit - TCR
  [7] PAR — Password Auto-sequence Request Bit - PAR
  [6] UR — Unlock Restriction Request Control Bit - UR
  [5] IR1 — Input Frequency Request Control - IR1,IR0
  [3] DR — Disable Request Control Bit - DR
  [2] IR0 — Input Frequency Request Control - IR1,IR0
0x254 WDTCPU0SR 32-bit ro reset 0xFFFC0010
  [31:16] TIM — Timer Value - TIM
  [15:9] TCT — Timer Check Tolerance - TCT
  [8] TCS — Timer Check Status Flag - TCS
  [7] PAS — Password Auto-sequence Status Flag - PAS
  [6] US — SMU Unlock Restriction Status Flag - US
  [5] IS1 — Watchdog Input Clock Status - IS1,IS0
  [4] TO — Watchdog Time-Out Mode Flag - TO
  [3] DS — Watchdog Enable/Disable Status Flag - DS
  [2] IS0 — Watchdog Input Clock Status - IS1,IS0
  [1] OE — Watchdog Overflow Error Status Flag - OE
  [0] AE — Watchdog Access Error Status Flag - AE
0x258 WDTCPU1CON0 32-bit reset 0xFFFC000F
  fields as WDTCPU0CON0
0x25C WDTCPU1CON1 32-bit reset 0x8
  fields as WDTCPU0CON1
0x260 WDTCPU1SR 32-bit ro reset 0xFFFC0008
  fields as WDTCPU0SR
0x264 WDTCPU2CON0 32-bit reset 0xFFFC000F
  fields as WDTCPU0CON0
0x268 WDTCPU2CON1 32-bit reset 0x8
  fields as WDTCPU0CON1
0x26C WDTCPU2SR 32-bit ro reset 0xFFFC0008
  fields as WDTCPU0SR
0x29C EICON0 32-bit reset 0xFFFC000E — ENDINIT Global Control Register 0
  [31:16] REL ro — Reload Value for the ENDINIT Timeout Counter - REL
  [15:2] EPW — User-Definable ENDINIT Password Field - EPW
  [1] ENDINIT — End-of-Initialization Control Bit - ENDINIT
0x2A0 EICON1 32-bit — ENDINIT Global Control Register 1
  [5] IR1 — Input Frequency Request Control - IR1,IR0
  [3] DR — Disable Request Control Bit - DR
  [2] IR0 — Input Frequency Request Control - IR1,IR0
0x2A4 EISR 32-bit ro reset 0xFFFC0000 — ENDINIT Timeout Counter Status Register
  [31:16] TIM — Timer Value - TIM
  [5] IS1 — EI Timeout Input Clock Status - IS1,IS0
  [4] TO — EI Time-Out Mode Flag - TO
  [3] DS — EI Timeout Enable/Disable Status Flag - DS
  [2] IS0 — EI Timeout Input Clock Status - IS1,IS0
  [1] OE — EI Timeout Overflow Error Status Flag - OE
  [0] AE — EICON0 Access Error Status Flag - AE
0x2A8 WDTSCON0 32-bit reset 0xFFFC000E — Safety WDT Control Register 0
  fields as WDTCPU0CON0
0x2AC WDTSCON1 32-bit — Safety WDT Control Register 1
  [15:9] TCTR — Timer Check Tolerance Request - TCTR
  [8] TCR — Counter Check Request Bit - TCR
  [7] PAR — Password Auto-sequence Request Bit - PAR
  [6] UR — Unlock Restriction Request Control Bit - UR
  [5] IR1 — Input Frequency Request Control - IR1,IR0
  [3] DR — Disable Request Control Bit - DR
  [2] IR0 — Input Frequency Request Control - IR1,IR0
  [0] CLRIRF — Clear Internal Reset Flag - CLRIRF
0x2B0 WDTSSR 32-bit ro reset 0xFFFC0010 — Safety WDT Status Register
  fields as WDTCPU0SR
0x2B4 SEICON0 32-bit reset 0xFFFC000E — Safety ENDINIT Control Register 0
  [31:16] REL ro — Reload Value for the Safety ENDINIT Timeout Counter - REL
  [15:2] EPW — User-Definable Safety ENDINIT Password Field - EPW
  [1] ENDINIT — End-of-Initialization Control Bit - ENDINIT
0x2B8 SEICON1 32-bit — Safety ENDINIT Control Register 1
  fields as EICON1
0x2BC SEISR 32-bit ro reset 0xFFFC0000 — Safety ENDINIT Timeout Status Register
  [31:16] TIM — Timer Value - TIM
  [5] IS1 — SEI Timeout Input Clock Status - IS0, IS1
  [4] TO — SEI Time-Out Mode Flag - TO
  [3] DS — SEI Enable/Disable Status Flag - DS
  [2] IS0 — SEI Timeout Input Clock Status - IS0, IS1
  [1] OE — SEI Timeout Overflow Error Status Flag - OE
  [0] AE — SEICON0 Access Error Status Flag - AE
0x3F0 ACCEN11 32-bit ro — Access Enable Register 11
0x3F4 ACCEN10 32-bit reset 0xFFFFFFFF — Access Enable Register 10
  [n] EN{n} (n=0..31) — Access Enable for Master TAG ID {n} - EN{n}
0x3F8 ACCEN01 32-bit ro — Access Enable Register 01
0x3FC ACCEN00 32-bit reset 0xFFFFFFFF — Access Enable Register 00
  [n] EN{n} (n=0..31) — Access Enable for Master TAG ID {n} - EN{n}
